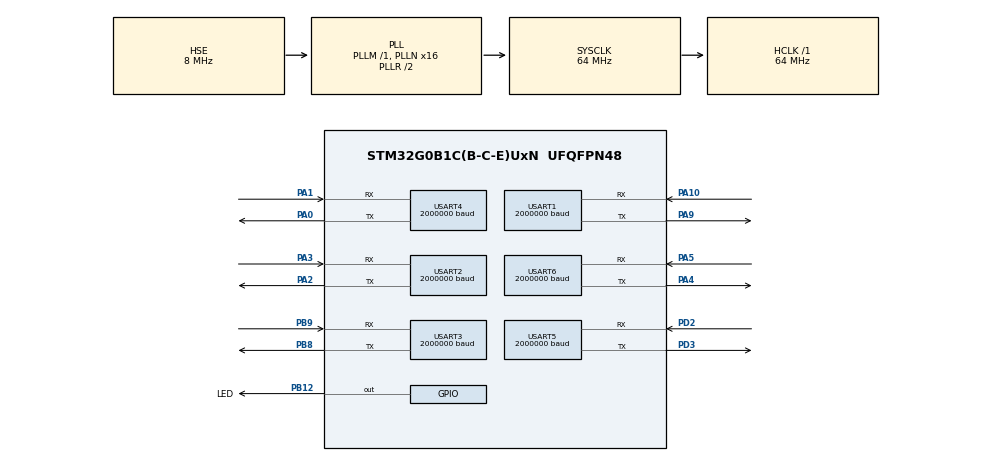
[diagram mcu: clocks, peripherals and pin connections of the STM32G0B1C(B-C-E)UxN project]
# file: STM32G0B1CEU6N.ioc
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Dma.Request0=USART1_RX
Dma.Request1=USART1_TX
Dma.Request10=USART6_RX
Dma.Request11=USART6_TX
Dma.Request2=USART2_RX
Dma.Request3=USART2_TX
Dma.Request4=USART3_RX
Dma.Request5=USART3_TX
Dma.Request6=USART4_RX
Dma.Request7=USART4_TX
Dma.Request8=USART5_RX
Dma.Request9=USART5_TX
Dma.USART1_RX.0.Direction=DMA_PERIPH_TO_MEMORY
Dma.USART1_RX.0.EventEnable=DISABLE
Dma.USART1_RX.0.Instance=DMA1_Channel1
Dma.USART1_RX.0.MemDataAlignment=DMA_MDATAALIGN_BYTE
Dma.USART1_RX.0.MemInc=DMA_MINC_ENABLE
Dma.USART1_RX.0.Mode=DMA_CIRCULAR
Dma.USART1_RX.0.PeriphDataAlignment=DMA_PDATAALIGN_BYTE
Dma.USART1_RX.0.PeriphInc=DMA_PINC_DISABLE
Dma.USART1_RX.0.Polarity=HAL_DMAMUX_REQ_GEN_RISING
Dma.USART1_RX.0.Priority=DMA_PRIORITY_LOW
Dma.USART1_RX.0.RequestNumber=1
Dma.USART1_RX.0.SignalID=NONE
Dma.USART1_RX.0.SyncEnable=DISABLE
Dma.USART1_RX.0.SyncPolarity=HAL_DMAMUX_SYNC_NO_EVENT
Dma.USART1_RX.0.SyncRequestNumber=1
Dma.USART1_RX.0.SyncSignalID=NONE
Dma.USART1_TX.1.Direction=DMA_MEMORY_TO_PERIPH
Dma.USART1_TX.1.EventEnable=DISABLE
Dma.USART1_TX.1.Instance=DMA1_Channel2
Dma.USART1_TX.1.MemDataAlignment=DMA_MDATAALIGN_BYTE
Dma.USART1_TX.1.MemInc=DMA_MINC_ENABLE
Dma.USART1_TX.1.Mode=DMA_NORMAL
Dma.USART1_TX.1.PeriphDataAlignment=DMA_PDATAALIGN_BYTE
Dma.USART1_TX.1.PeriphInc=DMA_PINC_DISABLE
Dma.USART1_TX.1.Polarity=HAL_DMAMUX_REQ_GEN_RISING
Dma.USART1_TX.1.Priority=DMA_PRIORITY_LOW
Dma.USART1_TX.1.RequestNumber=1
Dma.USART1_TX.1.SignalID=NONE
Dma.USART1_TX.1.SyncEnable=DISABLE
Dma.USART1_TX.1.SyncPolarity=HAL_DMAMUX_SYNC_NO_EVENT
Dma.USART1_TX.1.SyncRequestNumber=1
Dma.USART1_TX.1.SyncSignalID=NONE
Dma.USART2_RX.2.Direction=DMA_PERIPH_TO_MEMORY
Dma.USART2_RX.2.EventEnable=DISABLE
Dma.USART2_RX.2.Instance=DMA1_Channel3
Dma.USART2_RX.2.MemDataAlignment=DMA_MDATAALIGN_BYTE
Dma.USART2_RX.2.MemInc=DMA_MINC_ENABLE
Dma.USART2_RX.2.Mode=DMA_CIRCULAR
Dma.USART2_RX.2.PeriphDataAlignment=DMA_PDATAALIGN_BYTE
Dma.USART2_RX.2.PeriphInc=DMA_PINC_DISABLE
Dma.USART2_RX.2.Polarity=HAL_DMAMUX_REQ_GEN_RISING
Dma.USART2_RX.2.Priority=DMA_PRIORITY_LOW
Dma.USART2_RX.2.RequestNumber=1
Dma.USART2_RX.2.SignalID=NONE
Dma.USART2_RX.2.SyncEnable=DISABLE
Dma.USART2_RX.2.SyncPolarity=HAL_DMAMUX_SYNC_NO_EVENT
Dma.USART2_RX.2.SyncRequestNumber=1
Dma.USART2_RX.2.SyncSignalID=NONE
Dma.USART2_TX.3.Direction=DMA_MEMORY_TO_PERIPH
Dma.USART2_TX.3.EventEnable=DISABLE
Dma.USART2_TX.3.Instance=DMA1_Channel4
Dma.USART2_TX.3.MemDataAlignment=DMA_MDATAALIGN_BYTE
Dma.USART2_TX.3.MemInc=DMA_MINC_ENABLE
Dma.USART2_TX.3.Mode=DMA_NORMAL
Dma.USART2_TX.3.PeriphDataAlignment=DMA_PDATAALIGN_BYTE
Dma.USART2_TX.3.PeriphInc=DMA_PINC_DISABLE
Dma.USART2_TX.3.Polarity=HAL_DMAMUX_REQ_GEN_RISING
Dma.USART2_TX.3.Priority=DMA_PRIORITY_LOW
Dma.USART2_TX.3.RequestNumber=1
Dma.USART2_TX.3.SignalID=NONE
Dma.USART2_TX.3.SyncEnable=DISABLE
Dma.USART2_TX.3.SyncPolarity=HAL_DMAMUX_SYNC_NO_EVENT
Dma.USART2_TX.3.SyncRequestNumber=1
Dma.USART2_TX.3.SyncSignalID=NONE
Dma.USART3_RX.4.Direction=DMA_PERIPH_TO_MEMORY
Dma.USART3_RX.4.EventEnable=DISABLE
Dma.USART3_RX.4.Instance=DMA1_Channel5
Dma.USART3_RX.4.MemDataAlignment=DMA_MDATAALIGN_BYTE
Dma.USART3_RX.4.MemInc=DMA_MINC_ENABLE
Dma.USART3_RX.4.Mode=DMA_CIRCULAR
Dma.USART3_RX.4.PeriphDataAlignment=DMA_PDATAALIGN_BYTE
Dma.USART3_RX.4.PeriphInc=DMA_PINC_DISABLE
Dma.USART3_RX.4.Polarity=HAL_DMAMUX_REQ_GEN_RISING
Dma.USART3_RX.4.Priority=DMA_PRIORITY_LOW
Dma.USART3_RX.4.RequestNumber=1
Dma.USART3_RX.4.SignalID=NONE
Dma.USART3_RX.4.SyncEnable=DISABLE
Dma.USART3_RX.4.SyncPolarity=HAL_DMAMUX_SYNC_NO_EVENT
Dma.USART3_RX.4.SyncRequestNumber=1
Dma.USART3_RX.4.SyncSignalID=NONE
Dma.USART3_TX.5.Direction=DMA_MEMORY_TO_PERIPH
Dma.USART3_TX.5.EventEnable=DISABLE
Dma.USART3_TX.5.Instance=DMA1_Channel6
Dma.USART3_TX.5.MemDataAlignment=DMA_MDATAALIGN_BYTE
Dma.USART3_TX.5.MemInc=DMA_MINC_ENABLE
Dma.USART3_TX.5.Mode=DMA_NORMAL
Dma.USART3_TX.5.PeriphDataAlignment=DMA_PDATAALIGN_BYTE
Dma.USART3_TX.5.PeriphInc=DMA_PINC_DISABLE
Dma.USART3_TX.5.Polarity=HAL_DMAMUX_REQ_GEN_RISING
Dma.USART3_TX.5.Priority=DMA_PRIORITY_LOW
Dma.USART3_TX.5.RequestNumber=1
Dma.USART3_TX.5.SignalID=NONE
Dma.USART3_TX.5.SyncEnable=DISABLE
Dma.USART3_TX.5.SyncPolarity=HAL_DMAMUX_SYNC_NO_EVENT
Dma.USART3_TX.5.SyncRequestNumber=1
Dma.USART3_TX.5.SyncSignalID=NONE
Dma.USART4_RX.6.Direction=DMA_PERIPH_TO_MEMORY
Dma.USART4_RX.6.EventEnable=DISABLE
Dma.USART4_RX.6.Instance=DMA1_Channel7
Dma.USART4_RX.6.MemDataAlignment=DMA_MDATAALIGN_BYTE
Dma.USART4_RX.6.MemInc=DMA_MINC_ENABLE
Dma.USART4_RX.6.Mode=DMA_CIRCULAR
Dma.USART4_RX.6.PeriphDataAlignment=DMA_PDATAALIGN_BYTE
Dma.USART4_RX.6.PeriphInc=DMA_PINC_DISABLE
Dma.USART4_RX.6.Polarity=HAL_DMAMUX_REQ_GEN_RISING
Dma.USART4_RX.6.Priority=DMA_PRIORITY_LOW
Dma.USART4_RX.6.RequestNumber=1
Dma.USART4_RX.6.SignalID=NONE
Dma.USART4_RX.6.SyncEnable=DISABLE
Dma.USART4_RX.6.SyncPolarity=HAL_DMAMUX_SYNC_NO_EVENT
Dma.USART4_RX.6.SyncRequestNumber=1
Dma.USART4_RX.6.SyncSignalID=NONE
Dma.USART4_TX.7.Direction=DMA_MEMORY_TO_PERIPH
Dma.USART4_TX.7.EventEnable=DISABLE
Dma.USART4_TX.7.Instance=DMA2_Channel1
Dma.USART4_TX.7.MemDataAlignment=DMA_MDATAALIGN_BYTE
Dma.USART4_TX.7.MemInc=DMA_MINC_ENABLE
Dma.USART4_TX.7.Mode=DMA_NORMAL
Dma.USART4_TX.7.PeriphDataAlignment=DMA_PDATAALIGN_BYTE
Dma.USART4_TX.7.PeriphInc=DMA_PINC_DISABLE
Dma.USART4_TX.7.Polarity=HAL_DMAMUX_REQ_GEN_RISING
Dma.USART4_TX.7.Priority=DMA_PRIORITY_LOW
Dma.USART4_TX.7.RequestNumber=1
Dma.USART4_TX.7.SignalID=NONE
Dma.USART4_TX.7.SyncEnable=DISABLE
Dma.USART4_TX.7.SyncPolarity=HAL_DMAMUX_SYNC_NO_EVENT
Dma.USART4_TX.7.SyncRequestNumber=1
Dma.USART4_TX.7.SyncSignalID=NONE
Dma.USART5_RX.8.Direction=DMA_PERIPH_TO_MEMORY
Dma.USART5_RX.8.EventEnable=DISABLE
Dma.USART5_RX.8.Instance=DMA2_Channel2
Dma.USART5_RX.8.MemDataAlignment=DMA_MDATAALIGN_BYTE
Dma.USART5_RX.8.MemInc=DMA_MINC_ENABLE
Dma.USART5_RX.8.Mode=DMA_CIRCULAR
Dma.USART5_RX.8.PeriphDataAlignment=DMA_PDATAALIGN_BYTE
Dma.USART5_RX.8.PeriphInc=DMA_PINC_DISABLE
Dma.USART5_RX.8.Polarity=HAL_DMAMUX_REQ_GEN_RISING
Dma.USART5_RX.8.Priority=DMA_PRIORITY_LOW
Dma.USART5_RX.8.RequestNumber=1
Dma.USART5_RX.8.SignalID=NONE
Dma.USART5_RX.8.SyncEnable=DISABLE
Dma.USART5_RX.8.SyncPolarity=HAL_DMAMUX_SYNC_NO_EVENT
Dma.USART5_RX.8.SyncRequestNumber=1
Dma.USART5_RX.8.SyncSignalID=NONE
Dma.USART5_TX.9.Direction=DMA_MEMORY_TO_PERIPH
Dma.USART5_TX.9.EventEnable=DISABLE
Dma.USART5_TX.9.Instance=DMA2_Channel3
Dma.USART5_TX.9.MemDataAlignment=DMA_MDATAALIGN_BYTE
Dma.USART5_TX.9.MemInc=DMA_MINC_ENABLE
Dma.USART5_TX.9.Mode=DMA_NORMAL
Dma.USART5_TX.9.PeriphDataAlignment=DMA_PDATAALIGN_BYTE
Dma.USART5_TX.9.PeriphInc=DMA_PINC_DISABLE
Dma.USART5_TX.9.Polarity=HAL_DMAMUX_REQ_GEN_RISING
Dma.USART5_TX.9.Priority=DMA_PRIORITY_LOW
Dma.USART5_TX.9.RequestNumber=1
Dma.USART5_TX.9.SignalID=NONE
Dma.USART5_TX.9.SyncEnable=DISABLE
Dma.USART5_TX.9.SyncPolarity=HAL_DMAMUX_SYNC_NO_EVENT
Dma.USART5_TX.9.SyncRequestNumber=1
Dma.USART5_TX.9.SyncSignalID=NONE
Dma.USART6_RX.10.Direction=DMA_PERIPH_TO_MEMORY
Dma.USART6_RX.10.EventEnable=DISABLE
Dma.USART6_RX.10.Instance=DMA2_Channel4
Dma.USART6_RX.10.MemDataAlignment=DMA_MDATAALIGN_BYTE
Dma.USART6_RX.10.MemInc=DMA_MINC_ENABLE
Dma.USART6_RX.10.Mode=DMA_CIRCULAR
Dma.USART6_RX.10.PeriphDataAlignment=DMA_PDATAALIGN_BYTE
Dma.USART6_RX.10.PeriphInc=DMA_PINC_DISABLE
Dma.USART6_RX.10.Polarity=HAL_DMAMUX_REQ_GEN_RISING
Dma.USART6_RX.10.Priority=DMA_PRIORITY_LOW
Dma.USART6_RX.10.RequestNumber=1
Dma.USART6_RX.10.SignalID=NONE
Dma.USART6_RX.10.SyncEnable=DISABLE
Dma.USART6_RX.10.SyncPolarity=HAL_DMAMUX_SYNC_NO_EVENT
Dma.USART6_RX.10.SyncRequestNumber=1
Dma.USART6_RX.10.SyncSignalID=NONE
Dma.USART6_TX.11.Direction=DMA_MEMORY_TO_PERIPH
Dma.USART6_TX.11.EventEnable=DISABLE
Dma.USART6_TX.11.Instance=DMA2_Channel5
Dma.USART6_TX.11.MemDataAlignment=DMA_MDATAALIGN_BYTE
Dma.USART6_TX.11.MemInc=DMA_MINC_ENABLE
Dma.USART6_TX.11.Mode=DMA_NORMAL
Dma.USART6_TX.11.PeriphDataAlignment=DMA_PDATAALIGN_BYTE
Dma.USART6_TX.11.PeriphInc=DMA_PINC_DISABLE
Dma.USART6_TX.11.Polarity=HAL_DMAMUX_REQ_GEN_RISING
Dma.USART6_TX.11.Priority=DMA_PRIORITY_LOW
Dma.USART6_TX.11.RequestNumber=1
Dma.USART6_TX.11.SignalID=NONE
Dma.USART6_TX.11.SyncEnable=DISABLE
Dma.USART6_TX.11.SyncPolarity=HAL_DMAMUX_SYNC_NO_EVENT
Dma.USART6_TX.11.SyncRequestNumber=1
Dma.USART6_TX.11.SyncSignalID=NONE
Mcu.Family=STM32G0
Mcu.Name=STM32G0B1C(B-C-E)UxN
Mcu.Package=UFQFPN48
NVIC.DMA1_Ch4_7_DMA2_Ch1_5_DMAMUX1_OVR_IRQn=true\:0\:0\:false\:false\:true\:false\:true\:true
NVIC.DMA1_Channel1_IRQn=true\:0\:0\:false\:false\:true\:false\:true\:true
NVIC.DMA1_Channel2_3_IRQn=true\:0\:0\:false\:false\:true\:false\:true\:true
NVIC.USART1_IRQn=true\:0\:0\:false\:false\:true\:true\:true\:true
NVIC.USART2_LPUART2_IRQn=true\:0\:0\:false\:false\:true\:true\:true\:true
NVIC.USART3_4_5_6_LPUART1_IRQn=true\:0\:0\:false\:false\:true\:true\:true\:true
PA0.Mode=Asynchronous
PA0.Signal=USART4_TX
PA1.Mode=Asynchronous
PA1.Signal=USART4_RX
PA10.Mode=Asynchronous
PA10.Signal=USART1_RX
PA2.Mode=Asynchronous
PA2.Signal=USART2_TX
PA3.Mode=Asynchronous
PA3.Signal=USART2_RX
PA4.Mode=Asynchronous
PA4.Signal=USART6_TX
PA5.Mode=Asynchronous
PA5.Signal=USART6_RX
PA9.Mode=Asynchronous
PA9.Signal=USART1_TX
PB12.GPIO_Label=LED
PB12.Signal=GPIO_Output
PB8.Mode=Asynchronous
PB8.Signal=USART3_TX
PB9.Mode=Asynchronous
PB9.Signal=USART3_RX
PD2.Mode=Asynchronous
PD2.Signal=USART5_RX
PD3.Mode=Asynchronous
PD3.Signal=USART5_TX
PF0-OSC_IN\ (PF0).Mode=HSE-External-Oscillator
PF0-OSC_IN\ (PF0).Signal=RCC_OSC_IN
PF1-OSC_OUT\ (PF1).Mode=HSE-External-Oscillator
PF1-OSC_OUT\ (PF1).Signal=RCC_OSC_OUT
ProjectManager.HeapSize=0x200
ProjectManager.StackSize=0x400
ProjectManager.TargetToolchain=STM32CubeIDE
RCC.ADCFreq_Value=64000000
RCC.AHBFreq_Value=64000000
RCC.CortexFreq_Value=64000000
RCC.EXTERNAL_CLOCK_VALUE=48000
RCC.HCLKFreq_Value=64000000
RCC.HSE_VALUE=8000000
RCC.HSI48_VALUE=48000000
RCC.HSI_VALUE=16000000
RCC.LSE_VALUE=32768
RCC.PLLN=16
RCC.PLLSourceVirtual=RCC_PLLSOURCE_HSE
RCC.SYSCLKFreq_VALUE=64000000
RCC.SYSCLKSource=RCC_SYSCLKSOURCE_PLLCLK
RCC.USBFreq_Value=48000000
RCC.VCOOutputFreq_Value=128000000
USART1.BaudRate=2000000
USART1.FIFOMode=FIFOMODE_DISABLE
USART1.RXFIFOThreshold=RXFIFO_THRESHOLD_HALFFULL
USART1.TXFIFOThreshold=TXFIFO_THRESHOLD_HALFFULL
USART1.VirtualMode-Asynchronous=VM_ASYNC
USART2.BaudRate=2000000
USART2.FIFOMode=FIFOMODE_DISABLE
USART2.RXFIFOThreshold=RXFIFO_THRESHOLD_HALFFULL
USART2.TXFIFOThreshold=TXFIFO_THRESHOLD_HALFFULL
USART2.VirtualMode-Asynchronous=VM_ASYNC
USART3.BaudRate=2000000
USART3.FIFOMode=FIFOMODE_DISABLE
USART3.RXFIFOThreshold=RXFIFO_THRESHOLD_HALFFULL
USART3.TXFIFOThreshold=TXFIFO_THRESHOLD_HALFFULL
USART3.VirtualMode-Asynchronous=VM_ASYNC
USART4.BaudRate=2000000
USART4.VirtualMode-Asynchronous=VM_ASYNC
USART5.BaudRate=2000000
USART5.VirtualMode-Asynchronous=VM_ASYNC
USART6.BaudRate=2000000
USART6.VirtualMode-Asynchronous=VM_ASYNC
VP_SYS_VS_DBSignals.Mode=DisableDeadBatterySignals
board=custom

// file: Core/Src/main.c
/* USER CODE BEGIN Header */
/**
 ******************************************************************************
 * @file           : main.c
 * @brief          : Main program body
 ******************************************************************************
 * @attention
 *
 * Copyright (c) 2025 STMicroelectronics.
 * All rights reserved.
 *
 * This software is licensed under terms that can be found in the LICENSE file
 * in the root directory of this software component.
 * If no LICENSE file comes with this software, it is provided AS-IS.
 *
 ******************************************************************************
 */
/* USER CODE END Header */
#include "main.h"
#include "dma.h"
#include "usart.h"
#include "gpio.h"

/* USER CODE BEGIN Includes */
#include "dma_map.h"

/* USER CODE END Includes */

/* USER CODE BEGIN PV */
//uint8_t RxBuffer[1000] = { 0 };
//uint8_t TxBuffer[10] = { 10, 20, 30, 40, 50, 60, 70, 80, 90, 100 };
/* USER CODE END PV */

void SystemClock_Config(void);

/* USER CODE BEGIN 0 */

/*****************************************************************************/
/**************************** Module 1 (source) ******************************/
/*****************************************************************************/
 uint8_t src_buf[1000] = { [0 ... 999] = 123 };

const map_entry_t module_tx_map[] = {
    { MEM_TO_PORT, .dst = UART_PORT4, .mem = src_buf, .size = 40 }
};

//const map_entry_t module_tx_map[] = {
//		{ FWD_TO_PORT, .src = UART_PORT1, .dst = UART_PORT4, .size = 120 }
//};

/*****************************************************************************/
/********************************* Module 2 **********************************/
/*****************************************************************************/
/* Topology: P6 receives from Module 1 P4.
   Then: store first 40, forward next 40 to Module 3 via P2,
         forward last 40 to Module 4 via P4. */
//const map_entry_t module_tx_map[] = {
//    // First 40 bytes → store
//    { PORT_TO_MEM, .src = UART_PORT6, .mem = port_mem_buf[P6], .size = 40 },
//
//    // Next 40 bytes → forward to Module 3 (Module 3 listens on P5)
//    { FWD_TO_PORT, .src = UART_PORT6, .dst = UART_PORT2, .size = 40 },
//
//    // Final 40 bytes → forward to Module 4 (Module 4 listens on P5)
//    { FWD_TO_PORT, .src = UART_PORT6, .dst = UART_PORT4, .size = 40 },
//};

/*****************************************************************************/
/********************************* Module 3 **********************************/
/*****************************************************************************/
//const map_entry_t module_tx_map[] = {
//    { PORT_TO_MEM, .src = UART_PORT5, .mem = port_mem_buf[P5], .size = 40 }
//};

/*****************************************************************************/
/********************************* Module 4 **********************************/
/*****************************************************************************/
//const map_entry_t module_tx_map[] = {
//    { PORT_TO_MEM, .src = UART_PORT5, .mem = port_mem_buf[P5], .size = 40 }
//};

const size_t module_tx_map_len = sizeof(module_tx_map) / sizeof(module_tx_map[0]);

/* USER CODE END 0 */

int main(void)
{

  /* MCU Configuration--------------------------------------------------------*/

  /* Reset of all peripherals, Initializes the Flash interface and the Systick. */
  HAL_Init();

  /* Configure the system clock */
  SystemClock_Config();

  /* Initialize all configured peripherals */
  MX_GPIO_Init();
  MX_DMA_Init();
  MX_USART1_UART_Init();
  MX_USART2_UART_Init();
  MX_USART3_UART_Init();
  MX_USART4_UART_Init();
  MX_USART5_UART_Init();
  MX_USART6_UART_Init();
  /* USER CODE BEGIN 2 */

    // Start the TX phase
//    MapTx_Start();

//  HAL_UART_Transmit_DMA(UART_PORT4, src_buf, 120);

  /* USER CODE END 2 */

  /* Infinite loop */
	while (1) {

	}
}

void SystemClock_Config(void)
{
  RCC_OscInitTypeDef RCC_OscInitStruct = {0};
  RCC_ClkInitTypeDef RCC_ClkInitStruct = {0};

  /** Configure the main internal regulator output voltage
  */
  HAL_PWREx_ControlVoltageScaling(PWR_REGULATOR_VOLTAGE_SCALE1);

  /** Initializes the RCC Oscillators according to the specified parameters
  * in the RCC_OscInitTypeDef structure.
  */
  RCC_OscInitStruct.OscillatorType = RCC_OSCILLATORTYPE_HSE;
  RCC_OscInitStruct.HSEState = RCC_HSE_ON;
  RCC_OscInitStruct.PLL.PLLState = RCC_PLL_ON;
  RCC_OscInitStruct.PLL.PLLSource = RCC_PLLSOURCE_HSE;
  RCC_OscInitStruct.PLL.PLLM = RCC_PLLM_DIV1;
  RCC_OscInitStruct.PLL.PLLN = 16;
  RCC_OscInitStruct.PLL.PLLP = RCC_PLLP_DIV2;
  RCC_OscInitStruct.PLL.PLLQ = RCC_PLLQ_DIV2;
  RCC_OscInitStruct.PLL.PLLR = RCC_PLLR_DIV2;
  if (HAL_RCC_OscConfig(&RCC_OscInitStruct) != HAL_OK)
  {
    Error_Handler();
  }

  /** Initializes the CPU, AHB and APB buses clocks
  */
  RCC_ClkInitStruct.ClockType = RCC_CLOCKTYPE_HCLK|RCC_CLOCKTYPE_SYSCLK
                              |RCC_CLOCKTYPE_PCLK1;
  RCC_ClkInitStruct.SYSCLKSource = RCC_SYSCLKSOURCE_PLLCLK;
  RCC_ClkInitStruct.AHBCLKDivider = RCC_SYSCLK_DIV1;
  RCC_ClkInitStruct.APB1CLKDivider = RCC_HCLK_DIV1;

  if (HAL_RCC_ClockConfig(&RCC_ClkInitStruct, FLASH_LATENCY_2) != HAL_OK)
  {
    Error_Handler();
  }
}

void Error_Handler(void)
{
	__disable_irq();
	while (1) {
	}
}
